VERSION "HIPBNYYYYYYYYYYYYYYYYYYYYYYYYYYYNNNNNNNNNN/4/%%%/4/'%**4NNN///"

NS_ :

BS_:

BU_: Vector__XXX

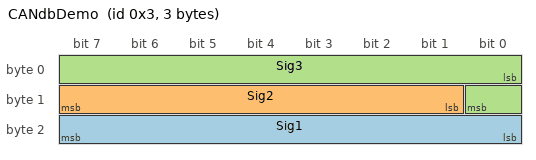
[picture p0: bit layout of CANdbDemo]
BO_ 3 CANdbDemo: 3 Vector__XXX
 SG_ Sig1 : 23|8@0+ (1,0) [0|0] "" Vector__XXX
 SG_ Sig2 : 15|7@0- (1,0) [0|0] "" Vector__XXX
 SG_ Sig3 : 0|9@1+ (1,0) [0|0] "" Vector__XXX

BO_ 2 DigitalOutputs: 2 Vector__XXX
 SG_ DigOut1 : 8|8@1+ (1,0) [0|0] "" Vector__XXX
 SG_ DigOut2 : 0|8@1+ (1,0) [0|0] "" Vector__XXX
